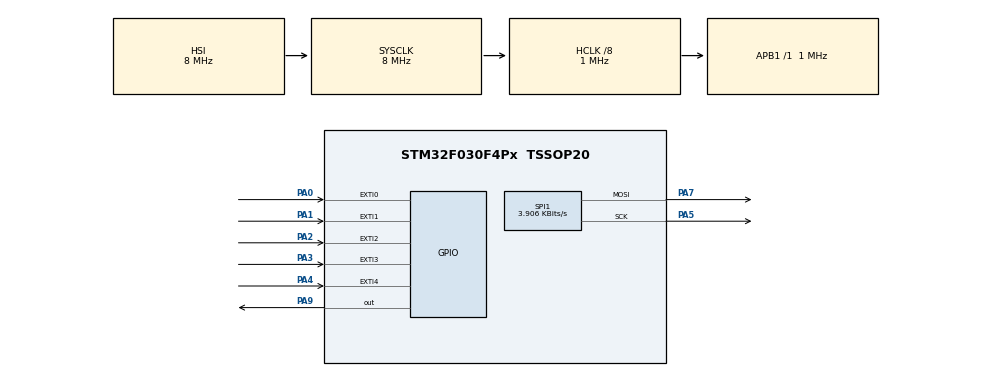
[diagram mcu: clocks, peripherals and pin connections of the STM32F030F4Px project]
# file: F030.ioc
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Mcu.Family=STM32F0
Mcu.Name=STM32F030F4Px
Mcu.Package=TSSOP20
NVIC.EXTI0_1_IRQn=true\:2\:0\:true\:false\:true\:true\:true\:true
NVIC.EXTI2_3_IRQn=true\:2\:0\:true\:false\:true\:true\:true\:true
NVIC.EXTI4_15_IRQn=true\:2\:0\:true\:false\:true\:true\:true\:true
NVIC.SPI1_IRQn=true\:0\:0\:false\:false\:true\:true\:true\:true
PA0.GPIO_ModeDefaultEXTI=GPIO_MODE_IT_FALLING
PA0.GPIO_PuPd=GPIO_PULLUP
PA0.Signal=GPXTI0
PA1.GPIO_ModeDefaultEXTI=GPIO_MODE_IT_FALLING
PA1.GPIO_PuPd=GPIO_PULLUP
PA1.Signal=GPXTI1
PA13.Mode=Serial_Wire
PA13.Signal=SYS_SWDIO
PA14.Mode=Serial_Wire
PA14.Signal=SYS_SWCLK
PA2.GPIO_ModeDefaultEXTI=GPIO_MODE_IT_FALLING
PA2.GPIO_PuPd=GPIO_PULLUP
PA2.Signal=GPXTI2
PA3.GPIO_ModeDefaultEXTI=GPIO_MODE_IT_FALLING
PA3.GPIO_PuPd=GPIO_PULLUP
PA3.Signal=GPXTI3
PA4.GPIO_ModeDefaultEXTI=GPIO_MODE_IT_FALLING
PA4.GPIO_PuPd=GPIO_PULLUP
PA4.Signal=GPXTI4
PA5.GPIO_PuPd=GPIO_PULLUP
PA5.GPIO_Speed=GPIO_SPEED_FREQ_HIGH
PA5.Mode=TX_Only_Simplex_Unidirect_Master
PA5.Signal=SPI1_SCK
PA7.GPIO_PuPd=GPIO_PULLUP
PA7.GPIO_Speed=GPIO_SPEED_FREQ_LOW
PA7.Mode=TX_Only_Simplex_Unidirect_Master
PA7.Signal=SPI1_MOSI
PA9.Signal=GPIO_Output
ProjectManager.HeapSize=0x200
ProjectManager.StackSize=0x400
ProjectManager.TargetToolchain=STM32CubeIDE
RCC.AHBCLKDivider=RCC_SYSCLK_DIV8
RCC.AHBFreq_Value=1000000
RCC.APB1Freq_Value=1000000
RCC.APB1TimFreq_Value=1000000
RCC.HCLKFreq_Value=1000000
RCC.PLLMUL=RCC_PLL_MUL16
RCC.SYSCLKFreq_VALUE=8000000
SPI1.BaudRatePrescaler=SPI_BAUDRATEPRESCALER_256
SPI1.CLKPhase=SPI_PHASE_2EDGE
SPI1.CLKPolarity=SPI_POLARITY_LOW
SPI1.CalculateBaudRate=3.906 KBits/s
SPI1.DataSize=SPI_DATASIZE_8BIT
SPI1.Direction=SPI_DIRECTION_2LINES
SPI1.Mode=SPI_MODE_MASTER
SPI1.VirtualType=VM_MASTER
board=custom

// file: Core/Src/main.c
/* USER CODE BEGIN Header */
/**
  ******************************************************************************
  * @file           : main.c
  * @brief          : Main program body
  ******************************************************************************
  * @attention
  *
  * Copyright (c) 2025 STMicroelectronics.
  * All rights reserved.
  *
  * This software is licensed under terms that can be found in the LICENSE file
  * in the root directory of this software component.
  * If no LICENSE file comes with this software, it is provided AS-IS.
  *
  ******************************************************************************
  */
/* USER CODE END Header */
#include "main.h"

/* USER CODE BEGIN Includes */
#include "app.h"
/* USER CODE END Includes */

SPI_HandleTypeDef hspi1;

void SystemClock_Config(void);
static void MX_GPIO_Init(void);
static void MX_SPI1_Init(void);

int main(void)
{

  /* MCU Configuration--------------------------------------------------------*/

  /* Reset of all peripherals, Initializes the Flash interface and the Systick. */
  HAL_Init();

  /* Configure the system clock */
  SystemClock_Config();

  /* Initialize all configured peripherals */
  MX_GPIO_Init();
  MX_SPI1_Init();

  /* Infinite loop */
  /* USER CODE BEGIN WHILE */
  app_start();
  while (1)
  {
	//HAL_SPI_Transmit_IT ( & hspi1 , TX_Buffer , 1 ); //Enviando em modo de interrupção
	//HAL_Delay ( 100 );
	  __WFI();
    /* USER CODE END WHILE */

  }
}

void SystemClock_Config(void)
{
  RCC_OscInitTypeDef RCC_OscInitStruct = {0};
  RCC_ClkInitTypeDef RCC_ClkInitStruct = {0};

  /** Initializes the RCC Oscillators according to the specified parameters
  * in the RCC_OscInitTypeDef structure.
  */
  RCC_OscInitStruct.OscillatorType = RCC_OSCILLATORTYPE_HSI;
  RCC_OscInitStruct.HSIState = RCC_HSI_ON;
  RCC_OscInitStruct.HSICalibrationValue = RCC_HSICALIBRATION_DEFAULT;
  RCC_OscInitStruct.PLL.PLLState = RCC_PLL_NONE;
  if (HAL_RCC_OscConfig(&RCC_OscInitStruct) != HAL_OK)
  {
    Error_Handler();
  }

  /** Initializes the CPU, AHB and APB buses clocks
  */
  RCC_ClkInitStruct.ClockType = RCC_CLOCKTYPE_HCLK|RCC_CLOCKTYPE_SYSCLK
                              |RCC_CLOCKTYPE_PCLK1;
  RCC_ClkInitStruct.SYSCLKSource = RCC_SYSCLKSOURCE_HSI;
  RCC_ClkInitStruct.AHBCLKDivider = RCC_SYSCLK_DIV8;
  RCC_ClkInitStruct.APB1CLKDivider = RCC_HCLK_DIV1;

  if (HAL_RCC_ClockConfig(&RCC_ClkInitStruct, FLASH_LATENCY_0) != HAL_OK)
  {
    Error_Handler();
  }
}

static void MX_SPI1_Init(void)
{

  /* SPI1 parameter configuration*/
  hspi1.Instance = SPI1;
  hspi1.Init.Mode = SPI_MODE_MASTER;
  hspi1.Init.Direction = SPI_DIRECTION_2LINES;
  hspi1.Init.DataSize = SPI_DATASIZE_8BIT;
  hspi1.Init.CLKPolarity = SPI_POLARITY_LOW;
  hspi1.Init.CLKPhase = SPI_PHASE_2EDGE;
  hspi1.Init.NSS = SPI_NSS_SOFT;
  hspi1.Init.BaudRatePrescaler = SPI_BAUDRATEPRESCALER_256;
  hspi1.Init.FirstBit = SPI_FIRSTBIT_MSB;
  hspi1.Init.TIMode = SPI_TIMODE_DISABLE;
  hspi1.Init.CRCCalculation = SPI_CRCCALCULATION_DISABLE;
  hspi1.Init.CRCPolynomial = 7;
  hspi1.Init.CRCLength = SPI_CRC_LENGTH_DATASIZE;
  hspi1.Init.NSSPMode = SPI_NSS_PULSE_DISABLE;
  if (HAL_SPI_Init(&hspi1) != HAL_OK)
  {
    Error_Handler();
  }

}

static void MX_GPIO_Init(void)
{
  GPIO_InitTypeDef GPIO_InitStruct = {0};

  /* GPIO Ports Clock Enable */
  __HAL_RCC_GPIOA_CLK_ENABLE();

  /*Configure GPIO pin Output Level */
  HAL_GPIO_WritePin(GPIOA, GPIO_PIN_9, GPIO_PIN_RESET);

  /*Configure GPIO pins : PA0 PA1 PA2 PA3
                           PA4 */
  GPIO_InitStruct.Pin = GPIO_PIN_0|GPIO_PIN_1|GPIO_PIN_2|GPIO_PIN_3
                          |GPIO_PIN_4;
  GPIO_InitStruct.Mode = GPIO_MODE_IT_FALLING;
  GPIO_InitStruct.Pull = GPIO_PULLUP;
  HAL_GPIO_Init(GPIOA, &GPIO_InitStruct);

  /*Configure GPIO pin : PA9 */
  GPIO_InitStruct.Pin = GPIO_PIN_9;
  GPIO_InitStruct.Mode = GPIO_MODE_OUTPUT_PP;
  GPIO_InitStruct.Pull = GPIO_NOPULL;
  GPIO_InitStruct.Speed = GPIO_SPEED_FREQ_LOW;
  HAL_GPIO_Init(GPIOA, &GPIO_InitStruct);

  /* EXTI interrupt init*/
  HAL_NVIC_SetPriority(EXTI0_1_IRQn, 2, 0);
  HAL_NVIC_EnableIRQ(EXTI0_1_IRQn);

  HAL_NVIC_SetPriority(EXTI2_3_IRQn, 2, 0);
  HAL_NVIC_EnableIRQ(EXTI2_3_IRQn);

  HAL_NVIC_SetPriority(EXTI4_15_IRQn, 2, 0);
  HAL_NVIC_EnableIRQ(EXTI4_15_IRQn);

}

void Error_Handler(void)
{
  __disable_irq();
  while (1)
  {
  }
}
